# STM32G031C4T6 register map
File version: 1.0
Registers are 32-bit, access not given, reset 0x0 unless marked. A register's access mark holds for its fields unless they carry their own. Offsets are from the block's base; [hi:lo] are bit positions; {n}, {i} and the like mark numbered series.

## CRS
Base 0x40006C00
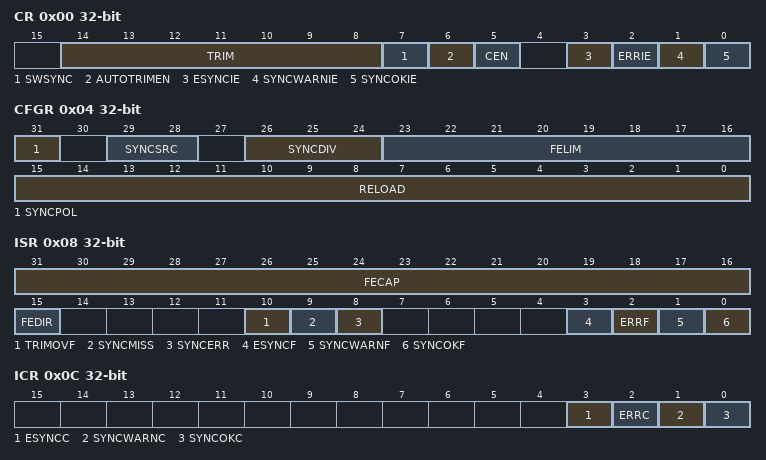
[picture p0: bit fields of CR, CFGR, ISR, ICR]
0x00 CR
  [14:8] TRIM, [7] SWSYNC, [6] AUTOTRIMEN, [5] CEN, [3] ESYNCIE, [2] ERRIE, [1] SYNCWARNIE, [0] SYNCOKIE
0x04 CFGR
  [31] SYNCPOL, [29:28] SYNCSRC, [26:24] SYNCDIV, [23:16] FELIM, [15:0] RELOAD
0x08 ISR
  [31:16] FECAP, [15] FEDIR, [10] TRIMOVF, [9] SYNCMISS, [8] SYNCERR, [3] ESYNCF, [2] ERRF, [1] SYNCWARNF, [0] SYNCOKF
0x0C ICR
  [3] ESYNCC, [2] ERRC, [1] SYNCWARNC, [0] SYNCOKC

## PWR
Base 0x40007000
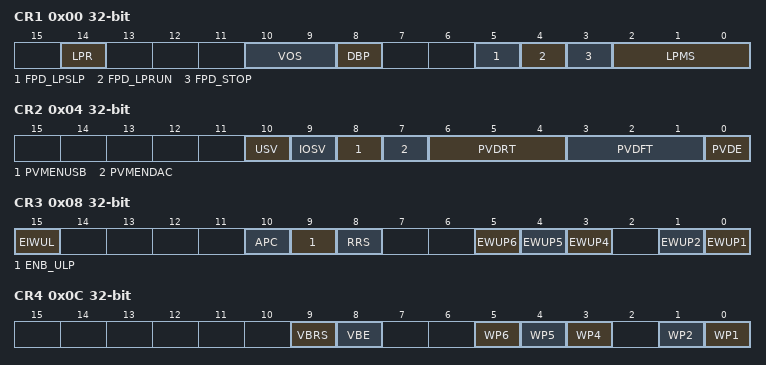
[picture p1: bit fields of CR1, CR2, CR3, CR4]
0x00 CR1
  [14] LPR, [10:9] VOS, [8] DBP, [5] FPD_LPSLP, [4] FPD_LPRUN, [3] FPD_STOP, [2:0] LPMS
0x04 CR2
  [10] USV, [9] IOSV, [8] PVMENUSB, [7] PVMENDAC, [6:4] PVDRT, [3:1] PVDFT, [0] PVDE
0x08 CR3
  [15] EIWUL, [10] APC, [9] ENB_ULP, [8] RRS, [5] EWUP6, [4] EWUP5, [3] EWUP4, [1] EWUP2, [0] EWUP1
0x0C CR4
  [9] VBRS, [8] VBE, [5] WP6, [4] WP5, [3] WP4, [1] WP2, [0] WP1
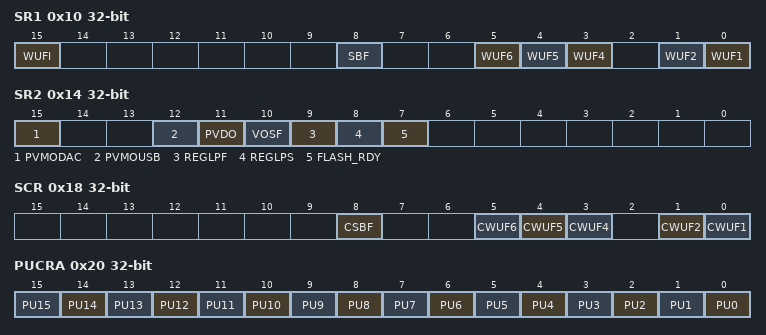
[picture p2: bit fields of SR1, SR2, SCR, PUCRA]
0x10 SR1
  [15] WUFI, [8] SBF, [5] WUF6, [4] WUF5, [3] WUF4, [1] WUF2, [0] WUF1
0x14 SR2
  [15] PVMODAC, [12] PVMOUSB, [11] PVDO, [10] VOSF, [9] REGLPF, [8] REGLPS, [7] FLASH_RDY
0x18 SCR
  [8] CSBF, [5] CWUF6, [4] CWUF5, [3] CWUF4, [1] CWUF2, [0] CWUF1
0x20 PUCRA
  [n] PU{n} (n=0..15)
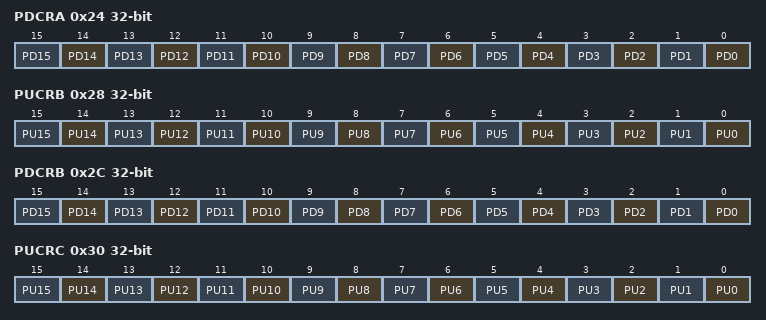
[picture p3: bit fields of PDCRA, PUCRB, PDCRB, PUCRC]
0x24 PDCRA
  [n] PD{n} (n=0..15)
0x28 PUCRB
  [n] PU{n} (n=0..15)
0x2C PDCRB
  [n] PD{n} (n=0..15)
0x30 PUCRC
  [n] PU{n} (n=0..15)
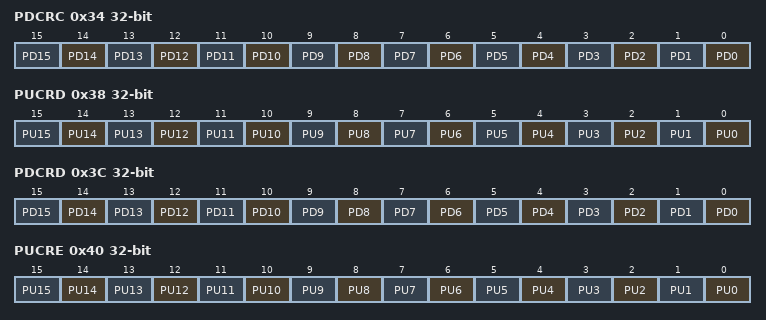
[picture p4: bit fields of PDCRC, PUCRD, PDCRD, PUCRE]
0x34 PDCRC
  [n] PD{n} (n=0..15)
0x38 PUCRD
  [n] PU{n} (n=0..15)
0x3C PDCRD
  [n] PD{n} (n=0..15)
0x40 PUCRE
  [n] PU{n} (n=0..15)
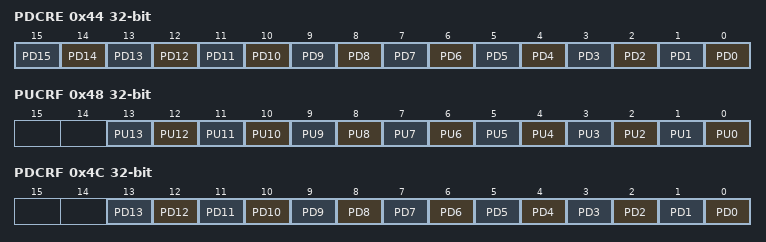
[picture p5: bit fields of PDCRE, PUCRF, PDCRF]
0x44 PDCRE
  [n] PD{n} (n=0..15)
0x48 PUCRF
  [n] PU{n} (n=0..13)
0x4C PDCRF
  [n] PD{n} (n=0..13)

## DAC
Base 0x40007400
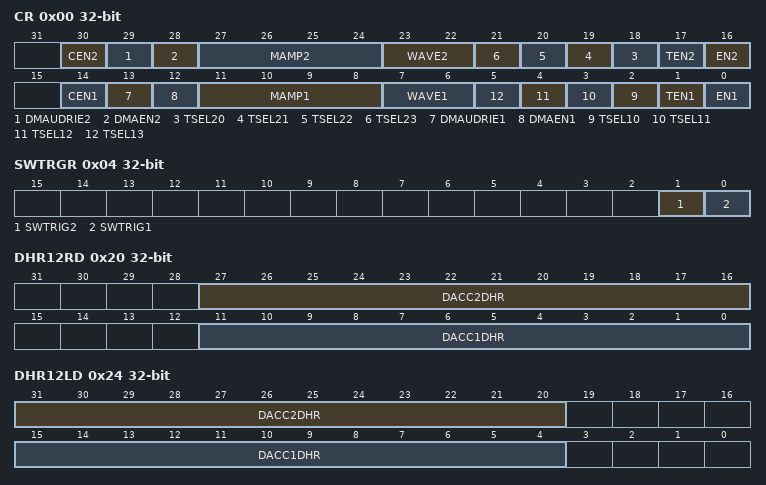
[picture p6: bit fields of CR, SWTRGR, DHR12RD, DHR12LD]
0x00 CR
  [30] CEN2, [29] DMAUDRIE2, [28] DMAEN2, [27:24] MAMP2, [23:22] WAVE2, [n-2] TSEL{n} (n=20..23), [17] TEN2, [16] EN2, [14] CEN1, [13] DMAUDRIE1, [12] DMAEN1, [11:8] MAMP1, [7:6] WAVE1, [n-8] TSEL{n} (n=10..13), [1] TEN1, [0] EN1
0x04 SWTRGR
  [1] SWTRIG2, [0] SWTRIG1
0x08 DHR12R1
  [11:0] DACC1DHR
0x0C DHR12L1
  [15:4] DACC1DHR
0x10 DHR8R1
  [7:0] DACC1DHR
0x14 DHR12R2
  [11:0] DACC2DHR
0x18 DHR12L2
  [15:4] DACC2DHR
0x1C DHR8R2
  [7:0] DACC2DHR
0x20 DHR12RD
  [27:16] DACC2DHR, [11:0] DACC1DHR
0x24 DHR12LD
  [31:20] DACC2DHR, [15:4] DACC1DHR
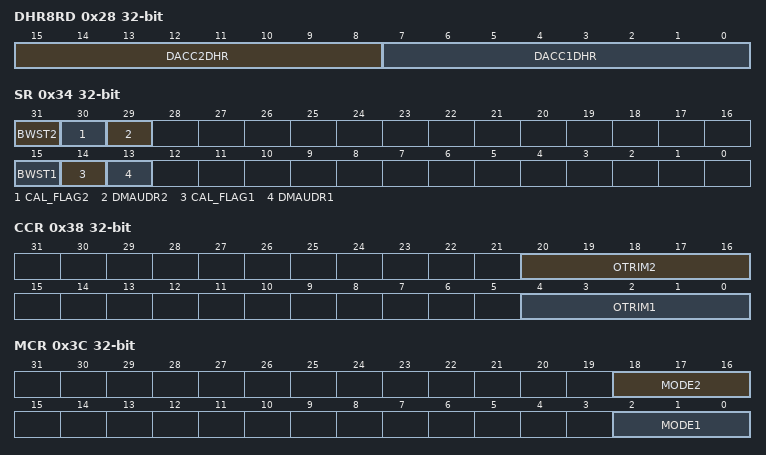
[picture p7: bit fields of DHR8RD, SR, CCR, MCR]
0x28 DHR8RD
  [15:8] DACC2DHR, [7:0] DACC1DHR
0x2C DOR1
  [11:0] DACC1DOR
0x30 DOR2
  [11:0] DACC2DOR
0x34 SR
  [31] BWST2, [30] CAL_FLAG2, [29] DMAUDR2, [15] BWST1, [14] CAL_FLAG1, [13] DMAUDR1
0x38 CCR
  [20:16] OTRIM2, [4:0] OTRIM1
0x3C MCR
  [18:16] MODE2, [2:0] MODE1
0x40 SHSR1
  [9:0] TSAMPLE1
0x44 SHSR2
  [9:0] TSAMPLE2
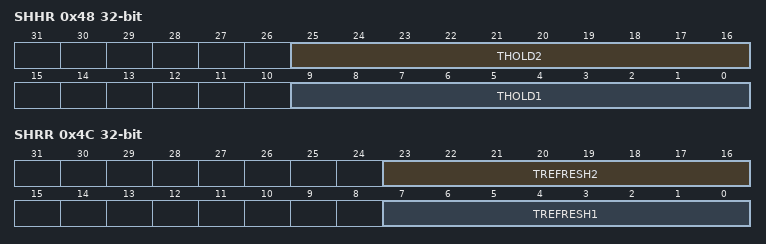
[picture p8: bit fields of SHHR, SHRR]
0x48 SHHR
  [25:16] THOLD2, [9:0] THOLD1
0x4C SHRR
  [23:16] TREFRESH2, [7:0] TREFRESH1

## CEC
Base 0x40007800
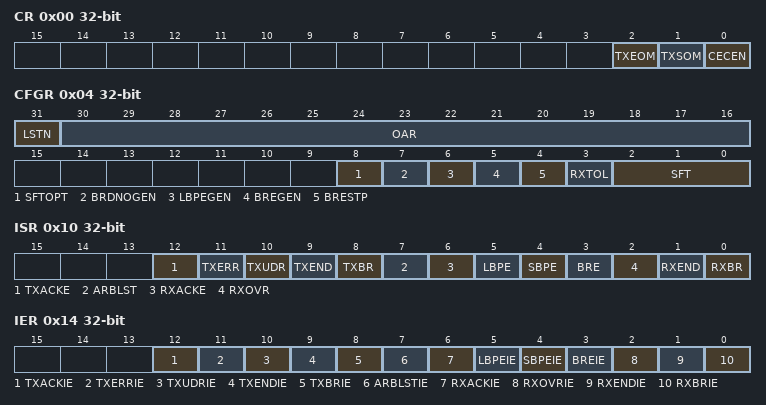
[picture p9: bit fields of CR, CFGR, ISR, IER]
0x00 CR
  [2] TXEOM, [1] TXSOM, [0] CECEN
0x04 CFGR
  [31] LSTN, [30:16] OAR, [8] SFTOPT, [7] BRDNOGEN, [6] LBPEGEN, [5] BREGEN, [4] BRESTP, [3] RXTOL, [2:0] SFT
0x08 TXDR
  [7:0] TXD
0x0C RXDR
  [7:0] RXD
0x10 ISR
  [12] TXACKE, [11] TXERR, [10] TXUDR, [9] TXEND, [8] TXBR, [7] ARBLST, [6] RXACKE, [5] LBPE, [4] SBPE, [3] BRE, [2] RXOVR, [1] RXEND, [0] RXBR
0x14 IER
  [12] TXACKIE, [11] TXERRIE, [10] TXUDRIE, [9] TXENDIE, [8] TXBRIE, [7] ARBLSTIE, [6] RXACKIE, [5] LBPEIE, [4] SBPEIE, [3] BREIE, [2] RXOVRIE, [1] RXENDIE, [0] RXBRIE

## LPTIM1
Base 0x40007C00
Same registers: LPTIM2 0x40009400
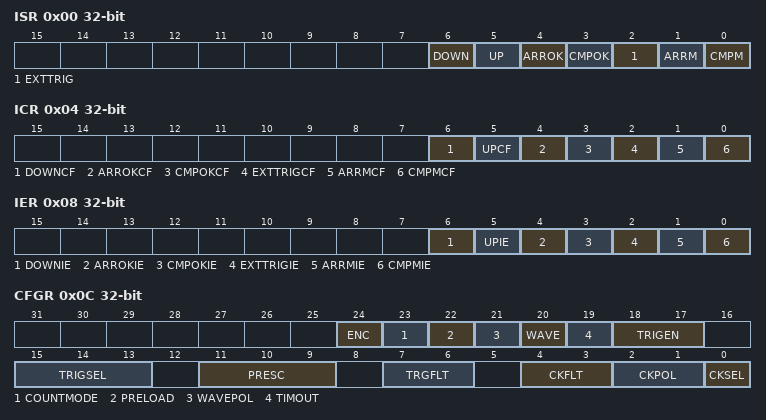
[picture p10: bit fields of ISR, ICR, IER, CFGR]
0x00 ISR
  [6] DOWN, [5] UP, [4] ARROK, [3] CMPOK, [2] EXTTRIG, [1] ARRM, [0] CMPM
0x04 ICR
  [6] DOWNCF, [5] UPCF, [4] ARROKCF, [3] CMPOKCF, [2] EXTTRIGCF, [1] ARRMCF, [0] CMPMCF
0x08 IER
  [6] DOWNIE, [5] UPIE, [4] ARROKIE, [3] CMPOKIE, [2] EXTTRIGIE, [1] ARRMIE, [0] CMPMIE
0x0C CFGR
  [24] ENC, [23] COUNTMODE, [22] PRELOAD, [21] WAVEPOL, [20] WAVE, [19] TIMOUT, [18:17] TRIGEN, [15:13] TRIGSEL, [11:9] PRESC, [7:6] TRGFLT, [4:3] CKFLT, [2:1] CKPOL, [0] CKSEL
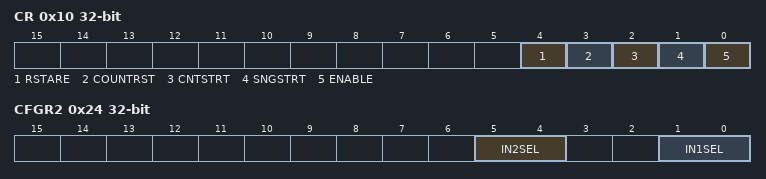
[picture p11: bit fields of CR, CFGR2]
0x10 CR
  [4] RSTARE, [3] COUNTRST, [2] CNTSTRT, [1] SNGSTRT, [0] ENABLE
0x14 CMP
  [15:0] CMP
0x18 ARR
  [15:0] ARR
0x1C CNT
  [15:0] CNT
0x24 CFGR2
  [5:4] IN2SEL, [1:0] IN1SEL
